# RTS5921 register map
Vendor: Realtek Semiconductor Corp.; Series: RTS5921 Series; File version: 0.01
CPU: ARMV8MBL r0p0, little endian, MPU, no FPU, VTOR, 3 interrupt priority bits
Registers are 32-bit, read-write, reset 0x0 unless marked. A register's access mark holds for its fields unless they carry their own. Offsets are from the block's base; [hi:lo] are bit positions; {n}, {i} and the like mark numbered series; 'fields as' and 'values as' point back to an identical list.

## USB_OUT_EP — USB OTG Out-Endpoint Controller
Base 0x40040B00
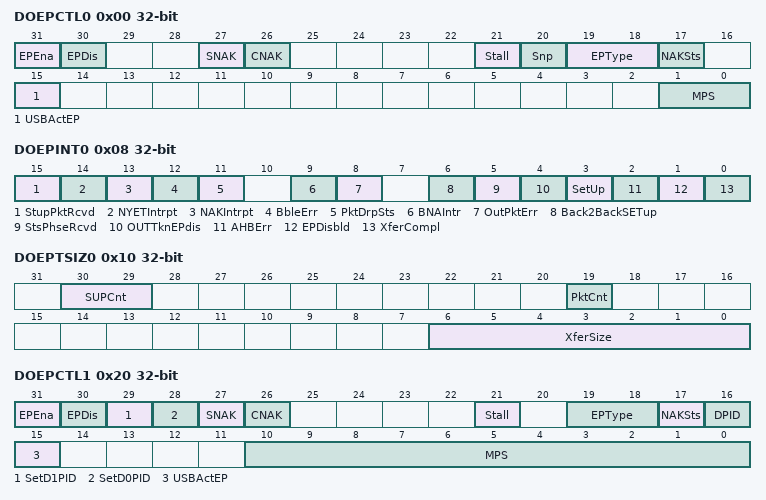
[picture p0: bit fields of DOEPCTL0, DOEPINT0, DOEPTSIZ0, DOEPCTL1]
0x00 DOEPCTL0 — Device Control OUT Endpoint 0 Control Register
  [31] EPEna — Endpoint enable (write 1 to set)
    0=INACTIVE (No action); 1=ACTIVE (Enable Endpoint)
  [30] EPDis ro — Endpoint disable status
  [27] SNAK wo — Set NAK (write 1 to set)
    0=NOSET (No action); 1=SET (Set NAK)
  [26] CNAK wo — Clear NAK (write 1 to clear)
    0=NOCLEAR (No action); 1=CLEAR (Clear NAK)
  [21] Stall — STALL handshake (write 1 to set, core clears)
    0=INACTIVE (No stall); 1=ACTIVE (Stall handshake)
  [20] Snp
  [19:18] EPType ro — Endpoint type (always control)
    0=CONTROL0 (Endpoint Control 0)
  [17] NAKSts ro — NAK status (0: non-NAK, 1: NAK handshakes)
    0=INACTIVE (Non-NAK handshakes); 1=ACTIVE (NAK handshakes)
  [15] USBActEP ro — USB active endpoint (always 1 for control 0)
  [1:0] MPS ro — Max packet size for EP0 (0:64B, 1:32B, 2:16B, 3:8B)
    0=BYTE64 (64 bytes); 1=BYTE32 (32 bytes); 2=BYTE16 (16 bytes); 3=BYTE8 (8 bytes)
0x08 DOEPINT0 — Device OUT Endpoint 0 Interrupt Register
  [15] StupPktRcvd — Setup packet received
    0=NOT_RCVD (No Setup packet received); 1=RCVD (Setup packet received)
  [14] NYETIntrpt — NYET interrupt
  [13] NAKIntrpt — NAK interrupt
  [12] BbleErr — Babble error
  [11] PktDrpSts — ISOC OUT packet dropped
  [9] BNAIntr — Buffer not available interrupt
  [8] OutPktErr — OUT packet error
  [6] Back2BackSETup — Back-to-back SETUP packets received
  [5] StsPhseRcvd — Status phase received (control OUT)
  [4] OUTTknEPdis — OUT token received when endpoint disabled
  [3] SetUp — SETUP phase done
  [2] AHBErr — AHB error
  [1] EPDisbld — Endpoint disabled interrupt
  [0] XferCompl — Transfer completed interrupt
0x10 DOEPTSIZ0 — Device OUT Endpoint 0 Transfer Size Register
  [30:29] SUPCnt — SETUP packet count
    1=ONEPACKET (1 packet); 2=TWOPACKET (2 packets); 3=THREEPACKET (3 packets)
  [19] PktCnt — Packet count
  [6:0] XferSize — Transfer size in bytes
{0x14+0x20*i} DOEPDMA{i} (i=0..15) — Device OUT Endpoint {i} DMA Address Register
0x1C DOEPDMAB0 — Device OUT Endpoint 0 DMA Buffer Address Register
0x20 DOEPCTL1 — Device Control OUT Endpoint 1 Control Register
  [31] EPEna — Endpoint enable
    0=INACTIVE (No action); 1=ACTIVE (Enable endpoint)
  [30] EPDis — Endpoint disable
    0=INACTIVE (No action); 1=ACTIVE (Disable endpoint)
  [29] SetD1PID wo — Set DATA1 PID / Odd frame
    0=DISABLED; 1=ENABLED (Set DATA1 PID or Odd frame)
  [28] SetD0PID wo — Set DATA0 PID / Even frame
    0=DISABLED; 1=ENABLED (Set DATA0 PID or Even frame)
  [27] SNAK wo — Set NAK
    0=INACTIVE (No set NAK); 1=ACTIVE (Set NAK)
  [26] CNAK wo — Clear NAK
    0=INACTIVE (No clear NAK); 1=ACTIVE (Clear NAK)
  [21] Stall — STALL handshake
  [19:18] EPType — Endpoint type
    0=CONTROL; 1=ISOCHRONOUS; 2=BULK; 3=INTERRUPT
  [17] NAKSts ro — NAK status
    0=NONNAK (Non-NAK handshake); 1=NAK (NAK handshake)
  [16] DPID ro — Endpoint DATA PID (micro)frame number
    0=DATA0/EVEN (DATA0 PID or even (micro)frame); 1=DATA1/ODD (DATA1 PID or odd (micro)frame)
  [15] USBActEP — USB active endpoint
  [10:0] MPS — Maximum packet size in bytes
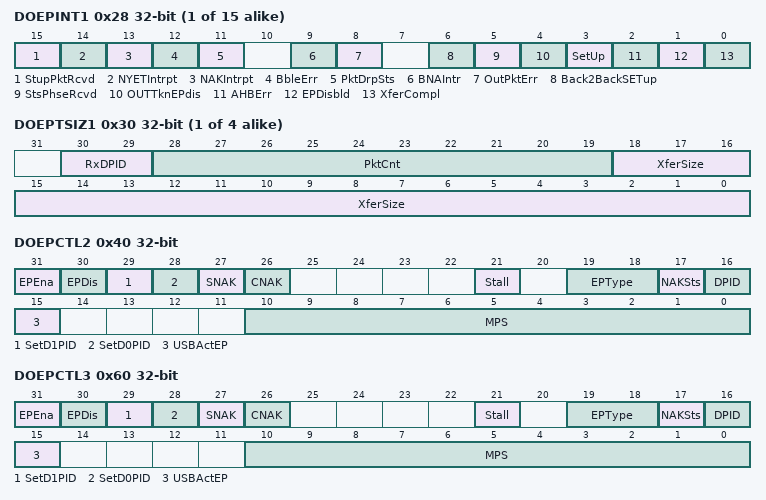
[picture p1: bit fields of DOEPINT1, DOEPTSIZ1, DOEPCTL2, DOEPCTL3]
{0x8+0x20*i} DOEPINT{i} (i=1..15) — Device OUT Endpoint {i} Interrupt Register
  [15] StupPktRcvd — Setup packet received
    values as DOEPINT0.StupPktRcvd
  [14] NYETIntrpt — NYET interrupt
  [13] NAKIntrpt — NAK interrupt
  [12] BbleErr — Babble error interrupt
  [11] PktDrpSts — ISOC OUT packet dropped
  [9] BNAIntr — Buffer not available interrupt
  [8] OutPktErr — OUT packet error
  [6] Back2BackSETup — Back-to-back SETUP packets received
  [5] StsPhseRcvd — Status phase received (control write)
  [4] OUTTknEPdis — OUT token received when endpoint disabled
  [3] SetUp — SETUP phase done
  [2] AHBErr — AHB error
  [1] EPDisbld — Endpoint disabled interrupt
  [0] XferCompl — Transfer completed interrupt
{0x10+0x20*i} DOEPTSIZ{i} (i=1..4) — Device OUT Endpoint {i} Transfer Size Register
  [30:29] RxDPID ro — Received data PID / Setup packet count
    0=DATA0; 1=DATA2PACKET1 (DATA2 or 1 packet); 2=DATA1PACKET2 (DATA1 or 2 packets); 3=MDATAPACKET3 (MDATA or 3 packets)
  [28:19] PktCnt — Packet count
  [18:0] XferSize — Transfer size in bytes
{0x1C+0x20*i} DOEPDMAB{i} ro (i=1..15) — Device OUT Endpoint {i} Buffer Address Register
0x40 DOEPCTL2 — Device Control OUT Endpoint 2 Control Register
  fields as DOEPCTL1
0x60 DOEPCTL3 — Device Control OUT Endpoint 2 Control Register
  fields as DOEPCTL1
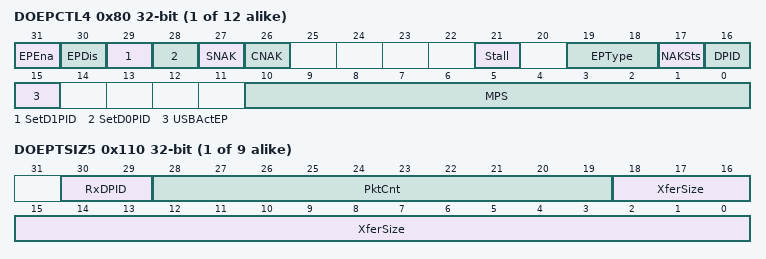
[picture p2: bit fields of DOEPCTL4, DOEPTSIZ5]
{0x0+0x20*i} DOEPCTL{i} (i=4..15) — Device Control OUT Endpoint {i} Control Register
  fields as DOEPCTL1
{0x70+0x20*i} DOEPTSIZ{i} (i=5..13) — Device OUT Endpoint {i} Transfer Size Register
  fields as DOEPTSIZ1
